AUTOSAR XML (schema 4-3-0)
package /SeatHeater
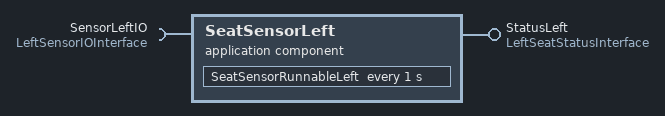
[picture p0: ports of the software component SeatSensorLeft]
  application sw component type SeatSensorLeft
    require port SensorLeftIO: nonqueued-receiver-com-spec=LeftSensorValue, required-interface=LeftSensorIOInterface
    provide port StatusLeft: nonqueued-sender-com-spec=PassengerOnLeftSeat, provided-interface=LeftSeatStatusInterface
    behavior SeatSensorLeft_InternalBehavior
      events:
        timing event SeatSensorLeftUpdateTimer: start-on-event=SeatSensorRunnableLeft, period=1
      runnable SeatSensorRunnableLeft
        data-send-points:
          access SeatSensorLeftStatusAccess: accessed-variable=StatusLeft.PassengerOnLeftSeat
        data-receive-point-by-values:
          access SeatSensorLeftIOAccess: accessed-variable=SensorLeftIO.LeftSensorValue
  swc implementation SeatSensorLeft_Implementation: behavior=SeatSensorLeft_InternalBehavior
